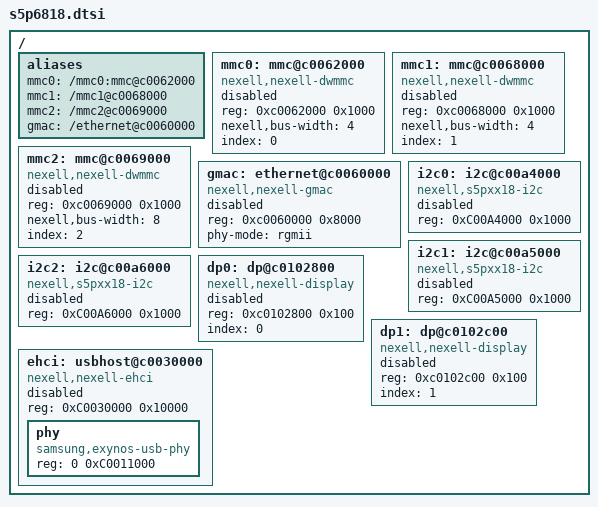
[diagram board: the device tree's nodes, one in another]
/*
 * (C) Copyright 2016 Nexell
 * Youngbok, Park <park@nexell.co.kr>
 *
 * SPDX-License-Identifier:      GPL-2.0+
 */

#include "skeleton.dtsi"
/ {
	aliases {
		mmc0 = "/mmc0:mmc@c0062000";
		mmc1 = "/mmc1@c0068000";
		mmc2 = "/mmc2@c0069000";
		gmac = "/ethernet@c0060000";
	};

	mmc0:mmc@c0062000 {
		#address-cells = <1>;
		#size-cells = <0>;
		compatible = "nexell,nexell-dwmmc";
		reg = <0xc0062000 0x1000>;
		nexell,bus-width = <4>;
		index = <0>;
		status = "disabled";
	};

	mmc1:mmc@c0068000 {
		#address-cells = <1>;
		#size-cells = <0>;
		compatible = "nexell,nexell-dwmmc";
		reg = <0xc0068000 0x1000>;
		nexell,bus-width = <4>;
		index = <1>;
		status = "disabled";
	};

	mmc2:mmc@c0069000 {
		#address-cells = <1>;
		#size-cells = <0>;
		compatible = "nexell,nexell-dwmmc";
		reg = <0xc0069000 0x1000>;
		nexell,bus-width = <8>;
		index = <2>;
		status = "disabled";
	};

	gmac:ethernet@c0060000 {
		compatible = "nexell,nexell-gmac";
		reg = <0xc0060000 0x8000>;
		phy-mode = "rgmii";
		status = "disabled";
	};

	i2c0:i2c@c00a4000 {
                compatible = "nexell,s5pxx18-i2c";
                reg = <0xC00A4000 0x1000>;
                #address-cells = <1>;
                #size-cells = <0>;
		status = "disabled";
        };

	i2c1:i2c@c00a5000 {
                compatible = "nexell,s5pxx18-i2c";
                reg = <0xC00A5000 0x1000>;
                #address-cells = <1>;
                #size-cells = <0>;
		status = "disabled";
        };

	i2c2:i2c@c00a6000 {
                compatible = "nexell,s5pxx18-i2c";
                reg = <0xC00A6000 0x1000>;
                #address-cells = <1>;
                #size-cells = <0>;
		status = "disabled";
        };

	dp0:dp@c0102800 {
		#address-cells = <1>;
		#size-cells = <0>;
		compatible = "nexell,nexell-display";
		reg = <0xc0102800 0x100>;
		index = <0>;
		status = "disabled";
	};

	dp1:dp@c0102c00 {
		#address-cells = <1>;
		#size-cells = <0>;
		compatible = "nexell,nexell-display";
		reg = <0xc0102c00 0x100>;
		index = <1>;
		status = "disabled";
	};

	ehci:usbhost@c0030000 {
		compatible = "nexell,nexell-ehci";
		reg = <0xC0030000 0x10000>;
		#address-cells = <1>;
		#size-cells = <1>;
		status = "disabled";
		phy {
			compatible = "samsung,exynos-usb-phy";
			reg = <0 0xC0011000>;
		};
	};
};
